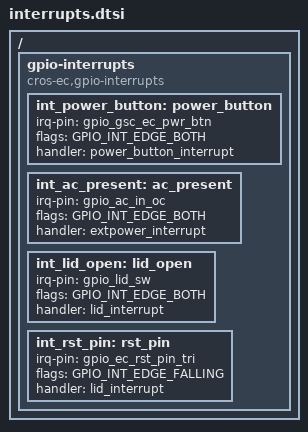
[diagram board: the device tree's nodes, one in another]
/* Copyright 2025 The ChromiumOS Authors
 * Use of this source code is governed by a BSD-style license that can be
 * found in the LICENSE file.
 */

/ {
	gpio-interrupts {
		compatible = "cros-ec,gpio-interrupts";

		int_power_button: power_button {
			irq-pin = <&gpio_gsc_ec_pwr_btn>;
			flags = <GPIO_INT_EDGE_BOTH>;
			handler = "power_button_interrupt";
		};
		int_ac_present: ac_present {
			irq-pin = <&gpio_ac_in_oc>;
			flags = <GPIO_INT_EDGE_BOTH>;
			handler = "extpower_interrupt";
		};
		int_lid_open: lid_open {
			irq-pin = <&gpio_lid_sw>;
			flags = <GPIO_INT_EDGE_BOTH>;
			handler = "lid_interrupt";
		};
		int_rst_pin: rst_pin {
			irq-pin = <&gpio_ec_rst_pin_tri>;
			flags = <GPIO_INT_EDGE_FALLING>;
			handler = "lid_interrupt";
			/* The handler of int_rst_pin should be dummy,
			 * but for experiment we just use other handler.
			 */
		};
	};
};
